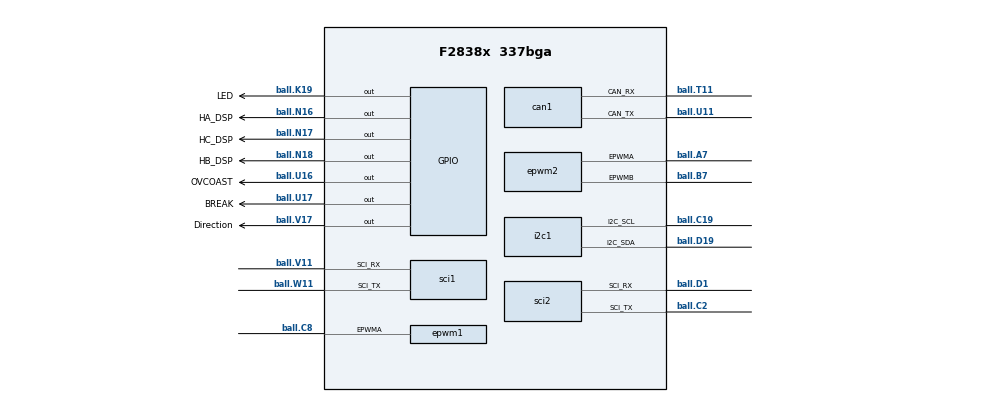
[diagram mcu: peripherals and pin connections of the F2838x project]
/**
 * @cliArgs --device "F2838x" --package "337bga" --part "F2838x_337bga" --product "C2000WARE@5.00.00.00"
 * @versions {"tool":"1.9.0+2015","templates":null}
 */

/**
 * Import the modules used in this configuration.
 */
const can   = scripting.addModule("/driverlib/can.js", {}, false);
const can1  = can.addInstance();
const epwm  = scripting.addModule("/driverlib/epwm.js", {}, false);
const epwm1 = epwm.addInstance();
const epwm2 = epwm.addInstance();
const gpio  = scripting.addModule("/driverlib/gpio.js", {}, false);
const gpio1 = gpio.addInstance();
const gpio2 = gpio.addInstance();
const gpio3 = gpio.addInstance();
const gpio4 = gpio.addInstance();
const gpio5 = gpio.addInstance();
const gpio6 = gpio.addInstance();
const gpio7 = gpio.addInstance();
const i2c   = scripting.addModule("/driverlib/i2c.js", {}, false);
const i2c1  = i2c.addInstance();
const sci   = scripting.addModule("/driverlib/sci.js", {}, false);
const sci1  = sci.addInstance();
const sci2  = sci.addInstance();

/**
 * Write custom configuration values to the imported modules.
 */
can1.$name                 = "myCAN0";
can1.msgObjs               = 2;
can1.loopbackMode          = "CAN_TEST_LBACK";
can1.interruptFlags        = ["CAN_INT_IE0"];
can1.interruptLine         = ["CAN_GLOBAL_INT_CANINT0"];
can1.enableInterrupt       = true;
can1.can.can_rxPin.$assign = "ball.T11";
can1.can.can_txPin.$assign = "ball.U11";
can1.msgObj1.$name         = "msgObj0";
can1.msgObj1.msgLen        = 8;
can1.msgObj1.msgID         = 256;
can1.msgObj1.msgType       = "CAN_MSG_OBJ_TYPE_TX";
can1.msgObj1.flags         = [];
can1.msgObj2.$name         = "msgObj1";
can1.msgObj2.msgID         = 256;
can1.msgObj2.msgLen        = 8;
can1.msgObj2.flags         = ["CAN_MSG_OBJ_RX_INT_ENABLE"];

epwm1.$name                 = "myEPWM1";
epwm1.epwm.epwmaPin.$assign = "ball.C8";

epwm2.$name                 = "myEPWM2";
epwm2.epwm.epwmaPin.$assign = "ball.A7";
epwm2.epwm.epwmbPin.$assign = "ball.B7";

gpio1.$name           = "LED";
gpio1.direction       = "GPIO_DIR_MODE_OUT";
gpio1.gpioPin.$assign = "ball.K19";

gpio2.$name           = "Direction";
gpio2.direction       = "GPIO_DIR_MODE_OUT";
gpio2.gpioPin.$assign = "ball.V17";

gpio3.$name           = "OVCOAST";
gpio3.direction       = "GPIO_DIR_MODE_OUT";
gpio3.gpioPin.$assign = "ball.U16";

gpio4.$name           = "BREAK";
gpio4.direction       = "GPIO_DIR_MODE_OUT";
gpio4.gpioPin.$assign = "ball.U17";

gpio5.$name           = "HA_DSP";
gpio5.gpioPin.$assign = "ball.N16";

gpio6.$name           = "HB_DSP";
gpio6.gpioPin.$assign = "ball.N18";

gpio7.$name           = "HC_DSP";
gpio7.gpioPin.$assign = "ball.N17";

i2c1.$name                  = "myI2C0";
i2c1.duty                   = "I2C_DUTYCYCLE_50";
i2c1.slaveAddress           = 0x48;
i2c1.bitCount               = "I2C_BITCOUNT_4";
i2c1.i2c.i2c_sdaPin.$assign = "ball.D19";
i2c1.i2c.i2c_sclPin.$assign = "ball.C19";

sci1.$name                 = "RS422";
sci1.useFifo               = false;
sci1.enabledInterrupts     = ["SCI_INT_RXRDY_BRKDT"];
sci1.baudRates             = 921600;
sci1.sci.$assign           = "SCIA";
sci1.sci.sci_rxPin.$assign = "ball.V11";
sci1.sci.sci_txPin.$assign = "ball.W11";

sci2.$name                 = "mySCI0";
sci2.useFifo               = false;
sci2.enabledInterrupts     = ["SCI_INT_RXRDY_BRKDT"];
sci2.loopback              = true;
sci2.sci.sci_rxPin.$assign = "ball.D1";
sci2.sci.sci_txPin.$assign = "ball.C2";

/**
 * Pinmux solution for unlocked pins/peripherals. This ensures that minor changes to the automatic solver in a future
 * version of the tool will not impact the pinmux you originally saw.  These lines can be completely deleted in order to
 * re-solve from scratch.
 */
can1.can.$suggestSolution            = "CANA";
epwm1.epwm.$suggestSolution          = "EPWM1";
epwm1.epwm.epwmbPin.$suggestSolution = "ball.D8";
epwm2.epwm.$suggestSolution          = "EPWM2";
i2c1.i2c.$suggestSolution            = "I2CA";
sci2.sci.$suggestSolution            = "SCIC";
